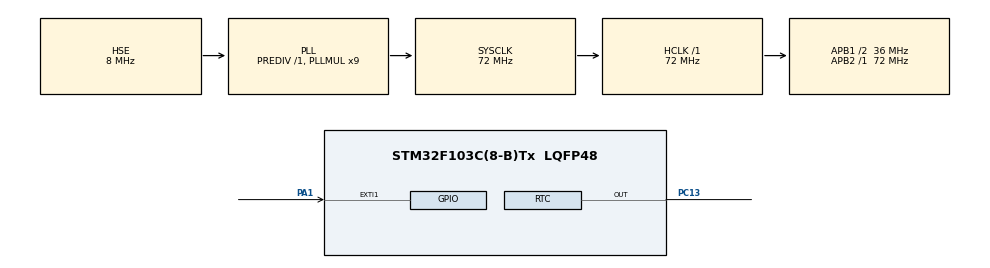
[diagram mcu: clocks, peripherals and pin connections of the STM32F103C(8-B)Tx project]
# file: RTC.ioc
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Mcu.Family=STM32F1
Mcu.Name=STM32F103C(8-B)Tx
Mcu.Package=LQFP48
NVIC.EXTI1_IRQn=true\:1\:0\:true\:false\:true\:true\:true\:true
NVIC.PriorityGroup=NVIC_PRIORITYGROUP_4
NVIC.RTC_Alarm_IRQn=true\:0\:0\:false\:false\:true\:true\:true\:true
PA1.Signal=GPXTI1
PA13.Mode=Serial_Wire
PA13.Signal=SYS_JTMS-SWDIO
PA14.Mode=Serial_Wire
PA14.Signal=SYS_JTCK-SWCLK
PC13-TAMPER-RTC.Mode=RTC OUT
PC13-TAMPER-RTC.Signal=RTC_OUT
PD0-OSC_IN.Mode=HSE-External-Oscillator
PD0-OSC_IN.Signal=RCC_OSC_IN
PD1-OSC_OUT.Mode=HSE-External-Oscillator
PD1-OSC_OUT.Signal=RCC_OSC_OUT
ProjectManager.HeapSize=0x200
ProjectManager.StackSize=0x400
ProjectManager.TargetToolchain=STM32CubeIDE
RCC.AHBFreq_Value=72000000
RCC.APB1CLKDivider=RCC_HCLK_DIV2
RCC.APB1Freq_Value=36000000
RCC.APB1TimFreq_Value=72000000
RCC.APB2Freq_Value=72000000
RCC.APB2TimFreq_Value=72000000
RCC.HCLKFreq_Value=72000000
RCC.PLLMUL=RCC_PLL_MUL9
RCC.PLLSourceVirtual=RCC_PLLSOURCE_HSE
RCC.SYSCLKFreq_VALUE=72000000
RCC.SYSCLKSource=RCC_SYSCLKSOURCE_PLLCLK
RCC.USBFreq_Value=72000000
RTC.AsynchPrediv=39999
RTC.AutoPrediv=0
RTC.Format=RTC_FORMAT_BIN
VP_RTC_VS_RTC_Activate.Mode=RTC_Enabled
VP_RTC_VS_RTC_Calendar.Mode=RTC_Calendar
board=custom

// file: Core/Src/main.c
/* USER CODE BEGIN Header */
/**
  ******************************************************************************
  * @file           : main.c
  * @brief          : Main program body
  ******************************************************************************
  * @attention
  *
  * Copyright (c) 2026 STMicroelectronics.
  * All rights reserved.
  *
  * This software is licensed under terms that can be found in the LICENSE file
  * in the root directory of this software component.
  * If no LICENSE file comes with this software, it is provided AS-IS.
  *
  ******************************************************************************
  */
/* USER CODE END Header */
#include "main.h"

RTC_HandleTypeDef hrtc;

/* USER CODE BEGIN PV */
RTC_TimeTypeDef Time={0};
RTC_AlarmTypeDef Alarm={0};
/* USER CODE END PV */

void SystemClock_Config(void);
static void MX_GPIO_Init(void);
static void MX_RTC_Init(void);
/* USER CODE BEGIN PFP */

void HAL_RTC_AlarmAEventCallback(RTC_HandleTypeDef *hrtc)
{

}

/* USER CODE END PFP */

int main(void)
{

  /* MCU Configuration--------------------------------------------------------*/

  /* Reset of all peripherals, Initializes the Flash interface and the Systick. */
  HAL_Init();

  /* Configure the system clock */
  SystemClock_Config();

  /* Initialize all configured peripherals */
  MX_GPIO_Init();
  MX_RTC_Init();

  /* Infinite loop */
  /* USER CODE BEGIN WHILE */
  while (1)
  {
	  HAL_RTC_GetTime(&hrtc, &Time,RTC_FORMAT_BIN);
	  HAL_RTC_GetAlarm(&hrtc, &Alarm, RTC_ALARM_A, RTC_FORMAT_BIN);
	  HAL_Delay(900);
    /* USER CODE END WHILE */

  }
}

void SystemClock_Config(void)
{
  RCC_OscInitTypeDef RCC_OscInitStruct = {0};
  RCC_ClkInitTypeDef RCC_ClkInitStruct = {0};
  RCC_PeriphCLKInitTypeDef PeriphClkInit = {0};

  /** Initializes the RCC Oscillators according to the specified parameters
  * in the RCC_OscInitTypeDef structure.
  */
  RCC_OscInitStruct.OscillatorType = RCC_OSCILLATORTYPE_LSI|RCC_OSCILLATORTYPE_HSE;
  RCC_OscInitStruct.HSEState = RCC_HSE_ON;
  RCC_OscInitStruct.HSEPredivValue = RCC_HSE_PREDIV_DIV1;
  RCC_OscInitStruct.HSIState = RCC_HSI_ON;
  RCC_OscInitStruct.LSIState = RCC_LSI_ON;
  RCC_OscInitStruct.PLL.PLLState = RCC_PLL_ON;
  RCC_OscInitStruct.PLL.PLLSource = RCC_PLLSOURCE_HSE;
  RCC_OscInitStruct.PLL.PLLMUL = RCC_PLL_MUL9;
  if (HAL_RCC_OscConfig(&RCC_OscInitStruct) != HAL_OK)
  {
    Error_Handler();
  }

  /** Initializes the CPU, AHB and APB buses clocks
  */
  RCC_ClkInitStruct.ClockType = RCC_CLOCKTYPE_HCLK|RCC_CLOCKTYPE_SYSCLK
                              |RCC_CLOCKTYPE_PCLK1|RCC_CLOCKTYPE_PCLK2;
  RCC_ClkInitStruct.SYSCLKSource = RCC_SYSCLKSOURCE_PLLCLK;
  RCC_ClkInitStruct.AHBCLKDivider = RCC_SYSCLK_DIV1;
  RCC_ClkInitStruct.APB1CLKDivider = RCC_HCLK_DIV2;
  RCC_ClkInitStruct.APB2CLKDivider = RCC_HCLK_DIV1;

  if (HAL_RCC_ClockConfig(&RCC_ClkInitStruct, FLASH_LATENCY_2) != HAL_OK)
  {
    Error_Handler();
  }
  PeriphClkInit.PeriphClockSelection = RCC_PERIPHCLK_RTC;
  PeriphClkInit.RTCClockSelection = RCC_RTCCLKSOURCE_LSI;
  if (HAL_RCCEx_PeriphCLKConfig(&PeriphClkInit) != HAL_OK)
  {
    Error_Handler();
  }
}

static void MX_RTC_Init(void)
{

  RTC_TimeTypeDef sTime = {0};
  RTC_DateTypeDef DateToUpdate = {0};
  RTC_AlarmTypeDef sAlarm = {0};

  /** Initialize RTC Only
  */
  hrtc.Instance = RTC;
  hrtc.Init.AsynchPrediv = 39999;
  hrtc.Init.OutPut = RTC_OUTPUTSOURCE_ALARM;
  if (HAL_RTC_Init(&hrtc) != HAL_OK)
  {
    Error_Handler();
  }

  /** Initialize RTC and set the Time and Date
  */
  sTime.Hours = 0;
  sTime.Minutes = 0;
  sTime.Seconds = 0;

  if (HAL_RTC_SetTime(&hrtc, &sTime, RTC_FORMAT_BIN) != HAL_OK)
  {
    Error_Handler();
  }
  DateToUpdate.WeekDay = RTC_WEEKDAY_MONDAY;
  DateToUpdate.Month = RTC_MONTH_JANUARY;
  DateToUpdate.Date = 1;
  DateToUpdate.Year = 0;

  if (HAL_RTC_SetDate(&hrtc, &DateToUpdate, RTC_FORMAT_BIN) != HAL_OK)
  {
    Error_Handler();
  }

  /** Enable the Alarm A
  */
  sAlarm.AlarmTime.Hours = 0;
  sAlarm.AlarmTime.Minutes = 0;
  sAlarm.AlarmTime.Seconds = 10;
  sAlarm.Alarm = RTC_ALARM_A;
  if (HAL_RTC_SetAlarm_IT(&hrtc, &sAlarm, RTC_FORMAT_BIN) != HAL_OK)
  {
    Error_Handler();
  }

}

static void MX_GPIO_Init(void)
{
  GPIO_InitTypeDef GPIO_InitStruct = {0};

  /* GPIO Ports Clock Enable */
  __HAL_RCC_GPIOC_CLK_ENABLE();
  __HAL_RCC_GPIOD_CLK_ENABLE();
  __HAL_RCC_GPIOA_CLK_ENABLE();

  /*Configure GPIO pin : PA1 */
  GPIO_InitStruct.Pin = GPIO_PIN_1;
  GPIO_InitStruct.Mode = GPIO_MODE_IT_RISING;
  GPIO_InitStruct.Pull = GPIO_NOPULL;
  HAL_GPIO_Init(GPIOA, &GPIO_InitStruct);

  /* EXTI interrupt init*/
  HAL_NVIC_SetPriority(EXTI1_IRQn, 1, 0);
  HAL_NVIC_EnableIRQ(EXTI1_IRQn);

/* USER CODE BEGIN MX_GPIO_Init_2 */
  HAL_NVIC_SetPriority(RTC_Alarm_IRQn, 0, 0);
  HAL_NVIC_EnableIRQ(RTC_Alarm_IRQn);
/* USER CODE END MX_GPIO_Init_2 */
}

void Error_Handler(void)
{
  __disable_irq();
  while (1)
  {
  }
}
